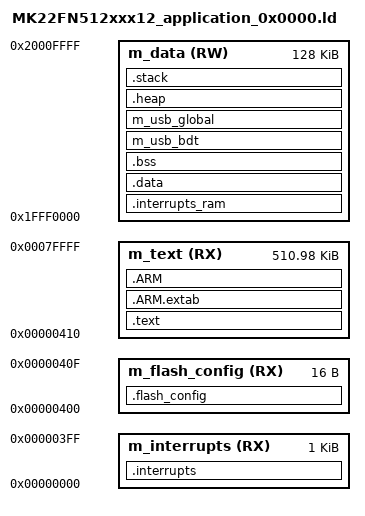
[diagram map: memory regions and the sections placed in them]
/*
** ###################################################################
**     Processors:          MK22FN512CAP12
**                          MK22FN512VDC12
**                          MK22FN512VFX12
**                          MK22FN512VLH12
**                          MK22FN512VLL12
**                          MK22FN512VMP12
**
**     Compiler:            GNU C Compiler
**
**     Abstract:
**         Linker file for the GNU C Compiler
**
**     Copyright (c) 2015 Freescale Semiconductor, Inc.
**     Copyright 2016-2018 NXP
**     All rights reserved.
**
**     SPDX-License-Identifier: BSD-3-Clause
**
**     http:                 www.nxp.com
**     mail:                 support@nxp.com
**
** ###################################################################
*/

/* Entry Point */
ENTRY(Reset_Handler)

HEAP_SIZE  = DEFINED(__heap_size__)  ? __heap_size__  : 0x0;
STACK_SIZE = DEFINED(__stack_size__) ? __stack_size__ : 0x1000;
M_VECTOR_RAM_SIZE = DEFINED(__ram_vector_table__) ? 0x0400 : 0x0;

/* Specify the memory areas */
MEMORY
{
  m_interrupts          (RX)  : ORIGIN = 0x00000000, LENGTH = 0x00000400
  m_flash_config        (RX)  : ORIGIN = 0x00000400, LENGTH = 0x00000010
  m_text                (RX)  : ORIGIN = 0x00000410, LENGTH = 0x0007FBF0
  m_data                (RW)  : ORIGIN = 0x1FFF0000, LENGTH = 0x00020000
}

GROUP (
  libnosys.a
  libgcc.a
  libc_nano.a
  libm.a
  libcr_newlib_none.a
)

/* Define output sections */
SECTIONS
{
  /* The startup code goes first into internal flash */
  .interrupts :
  {
    __VECTOR_TABLE = .;
    . = ALIGN(4);
    KEEP(*(.isr_vector))     /* Startup code */
    . = ALIGN(4);
  } > m_interrupts

  .flash_config :
  {
    . = ALIGN(4);
    KEEP(*(.FlashConfig))    /* Flash Configuration Field (FCF) */
    . = ALIGN(4);
  } > m_flash_config

  /* The program code and other data goes into internal flash */
  .text :
  {
    . = ALIGN(4);
    *(.text)                 /* .text sections (code) */
    *(.text*)                /* .text* sections (code) */
    *(.rodata)               /* .rodata sections (constants, strings, etc.) */
    *(.rodata*)              /* .rodata* sections (constants, strings, etc.) */
    . = ALIGN(4);
  } > m_text

  .ARM.extab :
  {
    *(.ARM.extab* .gnu.linkonce.armextab.*)
  } > m_text

  .ARM :
  {
    __exidx_start = .;
    *(.ARM.exidx*)
    __exidx_end = .;
  } > m_text

  __etext = .;    /* define a global symbol at end of code */
  __DATA_ROM = .; /* Symbol is used by startup for data initialization */

  .interrupts_ram :
  {
    . = ALIGN(4);
    __VECTOR_RAM__ = .;
    __interrupts_ram_start__ = .; /* Create a global symbol at data start */
    *(.m_interrupts_ram)     /* This is a user defined section */
    . += M_VECTOR_RAM_SIZE;
    . = ALIGN(4);
    __interrupts_ram_end__ = .; /* Define a global symbol at data end */
  } > m_data

  __VECTOR_RAM = DEFINED(__ram_vector_table__) ? __VECTOR_RAM__ : ORIGIN(m_interrupts);
  __RAM_VECTOR_TABLE_SIZE_BYTES = DEFINED(__ram_vector_table__) ? (__interrupts_ram_end__ - __interrupts_ram_start__) : 0x0;

  .data : AT(__DATA_ROM)
  {
    . = ALIGN(4);
    __DATA_RAM = .;
    __data_start__ = .;      /* create a global symbol at data start */
    *(.data)                 /* .data sections */
    *(.data*)                /* .data* sections */
    . = ALIGN(4);
    __data_end__ = .;        /* define a global symbol at data end */
  } > m_data

  __DATA_END = __DATA_ROM + (__data_end__ - __data_start__);

  /* Uninitialized data section */
  .bss :
  {
    /* This is used by the startup in order to initialize the .bss section */
    . = ALIGN(4);
    __START_BSS = .;
    __bss_start__ = .;
    *(.bss)
    *(.bss*)
    *(COMMON)
    . = ALIGN(4);
    __bss_end__ = .;
    __END_BSS = .;
  } > m_data
  
  
  m_usb_bdt : 
  {
    . = ALIGN(512);
    __START_USBGLOBAL = .;
    *(m_usb_bdt)
    KEEP(*(m_usb_bdt))
  } > m_data
  
  m_usb_global : 
  {
    . = ALIGN(512);
    *(m_usb_global)
    KEEP(*(m_usb_global))
    __END_USBGLOBAL = .;
  } > m_data

  .heap :
  {
    . = ALIGN(8);
    __end__ = .;
    _pvHeapStart = .;
    PROVIDE(end = .);
    __HeapBase = .;
    . += HEAP_SIZE;
    __HeapLimit = .;
  } > m_data

  .stack :
  {
    . = ALIGN(8);
    __StackLimit = .;
    . += STACK_SIZE;
    __StackTop = .;
    __STACK_TOP = .;
    PROVIDE(__stack = __StackTop);
  } > m_data

  .ARM.attributes 0 : { *(.ARM.attributes) }

  ASSERT(__StackLimit >= __HeapLimit, "region m_data_2 overflowed with stack and heap")
}

